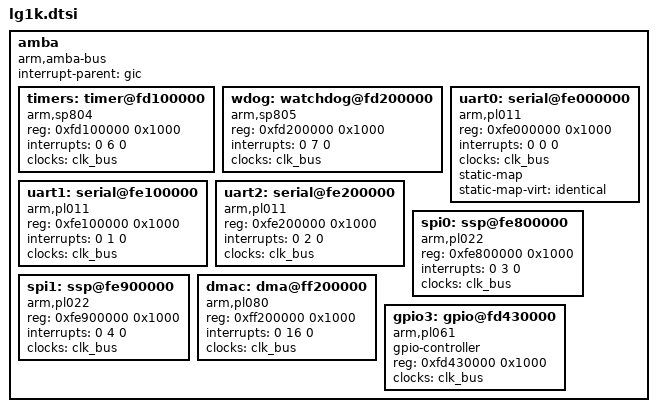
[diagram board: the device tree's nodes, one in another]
	amba {
		#address-cells = <1>;
		#size-cells = <1>;
		#interrupts-cells = <3>;

		compatible = "arm,amba-bus";
		interrupt-parent = <&gic>;
		ranges;

		timers: timer@fd100000 {
			compatible = "arm,sp804";
			reg = <0xfd100000 0x1000>;
			interrupts = <0 6 0>;
			clocks = <&clk_bus>;
			clock-names = "apb_pclk";
		};

		wdog: watchdog@fd200000 {
			compatible = "arm,sp805", "arm,primecell";
			reg = <0xfd200000 0x1000>;
			interrupts = <0 7 0>;
			clocks = <&clk_bus>;
			clock-names = "apb_pclk";
		};

		uart0: serial@fe000000 {
			compatible = "arm,pl011", "arm,primecell";
			reg = <0xfe000000 0x1000>;
			interrupts = <0 0 0>;
			clocks = <&clk_bus>;
			clock-names = "apb_pclk";
			static-map;
			static-map-virt = "identical";
		};

		uart1: serial@fe100000 {
			compatible = "arm,pl011", "arm,primecell";
			reg = <0xfe100000 0x1000>;
			interrupts = <0 1 0>;
			clocks = <&clk_bus>;
			clock-names = "apb_pclk";
		};

		uart2: serial@fe200000 {
			compatible = "arm,pl011", "arm,primecell";
			reg = <0xfe200000 0x1000>;
			interrupts = <0 2 0>;
			clocks = <&clk_bus>;
			clock-names = "apb_pclk";
		};

		spi0: ssp@fe800000 {
			compatible = "arm,pl022", "arm,primecell";
			reg = <0xfe800000 0x1000>;
			interrupts = <0 3 0>;
			clocks = <&clk_bus>;
			clock-names = "apb_pclk";
		};

		spi1: ssp@fe900000 {
			compatible = "arm,pl022", "arm,primecell";
			reg = <0xfe900000 0x1000>;
			interrupts = <0 4 0>;
			clocks = <&clk_bus>;
			clock-names = "apb_pclk";
		};

		dmac: dma@ff200000 {
			compatible = "arm,pl080", "arm,primecell";
			reg = <0xff200000 0x1000>;
			interrupts = <0 16 0>;
			clocks = <&clk_bus>;
			clock-names = "apb_pclk";

		};

		gpio3: gpio@fd430000 {
			#gpio-cells = <2>;
			compatible = "arm,pl061", "arm,primecell";
			gpio-controller;
			reg = <0xfd430000 0x1000>;
			clocks = <&clk_bus>;
			clock-names = "apb_pclk";
		};
	};
